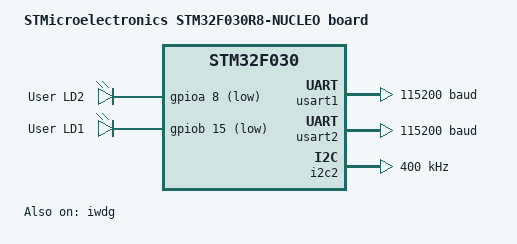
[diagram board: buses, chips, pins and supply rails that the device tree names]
/*
 * Copyright (c) 2017 RnDity Sp. z o.o.
 *
 * SPDX-License-Identifier: Apache-2.0
 */

/dts-v1/;
#include <st/f0/stm32f030X8.dtsi>

/ {
	model = "STMicroelectronics STM32F030R8-NUCLEO board";
	compatible = "st,stm32f030r8-nucleo", "st,stm32f030";

	chosen {
		zephyr,console = &usart2;
		zephyr,shell-uart = &usart2;
		zephyr,sram = &sram0;
		zephyr,flash = &flash0;
	};

	leds {
		compatible = "gpio-leds";
		green_led_2: led_2 {
			gpios = <&gpioa 8 GPIO_INT_ACTIVE_LOW>;
			label = "User LD2";
		};
		green_led_1: led_1 {
			gpios = <&gpiob 15 GPIO_INT_ACTIVE_LOW>;
			label = "User LD1";
		};
	};
/*
	gpio_keys {
		compatible = "gpio-keys";
		user_button1: button1 {
			label = "User1";
			gpios = <&gpiof 7 GPIO_INT_ACTIVE_LOW>;
		};
		user_button2: button2 {
			label = "User2";
			gpios = <&gpiof 6 GPIO_INT_ACTIVE_LOW>;
		};
		motor_key1: key1 {
			label = "Motor1";
			gpios = <&gpioa 1 GPIO_INT_ACTIVE_LOW>;
		};
		motor_key2: key2 {
			label = "Motor2";
			gpios = <&gpioa 1 GPIO_INT_ACTIVE_LOW>;
		};
	};
*/
	aliases {
		led0 = &green_led_2;
		led1 = &green_led_1;
		/*
		sw0 = &user_button1;
		sw1 = &user_button2;
		sw2 = &motor_key1;
		sw3 = &motor_key2;
		*/
	};
};

&usart1 {
	current-speed = <115200>;
	pinctrl-0 = <&usart1_pins_b>;
	pinctrl-names = "default";
	status = "ok";
};

&usart2 {
	current-speed = <115200>;
	pinctrl-0 = <&usart2_pins_a>;
	pinctrl-names = "default";
	status = "ok";
};

/*arduino_i2c: &i2c1 {
	status = "ok";
	clock-frequency = <I2C_BITRATE_FAST>;
};
*/
&i2c2 {
	status = "ok";
	clock-frequency = <I2C_BITRATE_FAST>;
};
/*
arduino_spi: &spi1 {
      status = "ok";
};

&spi2 {
      status = "ok";
};
*/

&iwdg {
	status = "ok";
};

/*&adc1 {
	status = "ok";
};*/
